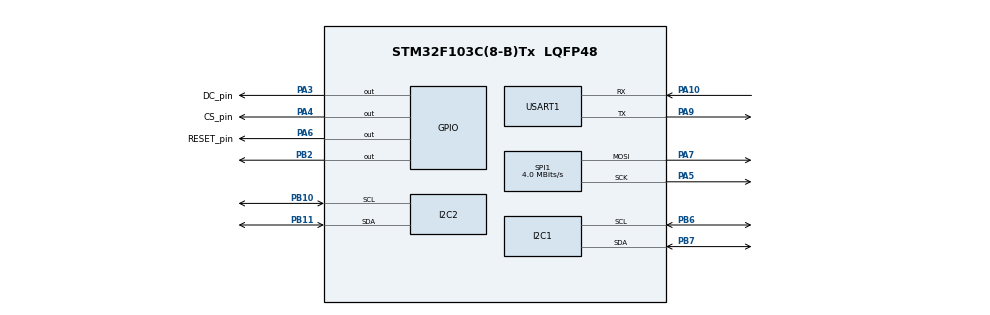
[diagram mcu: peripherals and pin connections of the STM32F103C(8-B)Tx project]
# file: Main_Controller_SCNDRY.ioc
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I2C1.OwnAddress=0x12
Mcu.Family=STM32F1
Mcu.Name=STM32F103C(8-B)Tx
Mcu.Package=LQFP48
NVIC.I2C1_ER_IRQn=true\:0\:0\:false\:false\:true\:true\:true\:true
NVIC.I2C1_EV_IRQn=true\:0\:0\:false\:false\:true\:true\:true\:true
NVIC.PriorityGroup=NVIC_PRIORITYGROUP_4
PA10.Mode=Asynchronous
PA10.Signal=USART1_RX
PA13.Mode=Serial_Wire
PA13.Signal=SYS_JTMS-SWDIO
PA14.Mode=Serial_Wire
PA14.Signal=SYS_JTCK-SWCLK
PA3.GPIO_Label=DC_pin
PA3.Signal=GPIO_Output
PA4.GPIO_Label=CS_pin
PA4.Signal=GPIO_Output
PA5.Mode=TX_Only_Simplex_Unidirect_Master
PA5.Signal=SPI1_SCK
PA6.GPIO_Label=RESET_pin
PA6.Signal=GPIO_Output
PA7.Mode=TX_Only_Simplex_Unidirect_Master
PA7.Signal=SPI1_MOSI
PA9.Mode=Asynchronous
PA9.Signal=USART1_TX
PB10.Mode=I2C
PB10.Signal=I2C2_SCL
PB11.Mode=I2C
PB11.Signal=I2C2_SDA
PB2.Signal=GPIO_Output
PB6.Mode=I2C
PB6.Signal=I2C1_SCL
PB7.Mode=I2C
PB7.Signal=I2C1_SDA
ProjectManager.HeapSize=0x200
ProjectManager.StackSize=0x400
ProjectManager.TargetToolchain=STM32CubeIDE
RCC.APB1Freq_Value=8000000
RCC.APB2Freq_Value=8000000
SPI1.CalculateBaudRate=4.0 MBits/s
SPI1.Direction=SPI_DIRECTION_2LINES
SPI1.Mode=SPI_MODE_MASTER
SPI1.VirtualType=VM_MASTER
USART1.VirtualMode=VM_ASYNC
board=custom

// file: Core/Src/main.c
//* USER CODE BEGIN Header */
/**
  ******************************************************************************
  * @file           : main.c
  * @brief          : Main program body
  ******************************************************************************
  * @attention
  *
  * Copyright (c) 2025 STMicroelectronics.
  * All rights reserved.
  *
  * This software is licensed under terms that can be found in the LICENSE file
  * in the root directory of this software component.
  * If no LICENSE file comes with this software, it is provided AS-IS.
  *
  ******************************************************************************
  */
/* USER CODE END Header */
#include "main.h"

/* USER CODE BEGIN Includes */
#include "I2C_Transmit.h"
#include "I2C_Receive.h"
#include "ssd1306.h"
#include "ssd1306_fonts.h"
#include "string.h"
#include "stdio.h"
/* USER CODE END Includes */

/* USER CODE BEGIN PD */
#define DO_Address 0x14
#define AO_Address 0x12
/* USER CODE END PD */

I2C_HandleTypeDef hi2c1;
I2C_HandleTypeDef hi2c2;

SPI_HandleTypeDef hspi1;

UART_HandleTypeDef huart1;

/* USER CODE BEGIN PV */
char analog_displayBuffer[4];
char digital_displayBuffer[9] = "";
/* USER CODE END PV */

void SystemClock_Config(void);
static void MX_GPIO_Init(void);
static void MX_I2C1_Init(void);
static void MX_I2C2_Init(void);
static void MX_SPI1_Init(void);
static void MX_USART1_UART_Init(void);

int main(void)
{

  /* MCU Configuration--------------------------------------------------------*/

  /* Reset of all peripherals, Initializes the Flash interface and the Systick. */
  HAL_Init();

  /* Configure the system clock */
  SystemClock_Config();

  /* Initialize all configured peripherals */
  MX_GPIO_Init();
  MX_I2C1_Init();
  MX_I2C2_Init();
  MX_SPI1_Init();
  MX_USART1_UART_Init();
  /* USER CODE BEGIN 2 */
  ssd1306_Init();
  uart_buffer[0] = 0xAA; // Start byte for data framing in ESP32
  /* USER CODE END 2 */

  /* Infinite loop */
  /* USER CODE BEGIN WHILE */
  while (1)
  {
	  /* For receiving data in interrupt mode*/
	HAL_I2C_EnableListen_IT(&hi2c1);

	/*for(int i = 0; i < 8; i++){
		digital_displayBuffer[i] = decodedBits[i] ? '1' : '0';
	}
	digital_displayBuffer[8] = '\0';

	sprintf(analog_displayBuffer, "%hu",analog_val);

	ssd1306_Fill(Black); // For the background color selection
	ssd1306_SetCursor(2, 0);	// To point to a pixel to start writing from
	ssd1306_WriteString("AO: ", Font_11x18, White); // To write the desired text on screen
	ssd1306_SetCursor(77,0);
	ssd1306_WriteString(analog_displayBuffer, Font_11x18 , White);
	ssd1306_SetCursor(2, 20);	// To point to a pixel to start writing from
	ssd1306_WriteString("DO: ", Font_11x18, White); // To write the desired text on screen
	ssd1306_SetCursor(35,20);
	ssd1306_WriteString(digital_displayBuffer, Font_11x18 , White);
	ssd1306_UpdateScreen();*/
	/* Transferring received data to digital output module
	* and analog output module
	*/
	//writeData(&digital_data,DO_Address,1);
	//HAL_UART_Transmit(&huart1, uart_buffer, 4, 1);
	writeData(analog_data, AO_Address, 2);
	//HAL_Delay(250);
    /* USER CODE END WHILE */

  }
}

void SystemClock_Config(void)
{
  RCC_OscInitTypeDef RCC_OscInitStruct = {0};
  RCC_ClkInitTypeDef RCC_ClkInitStruct = {0};

  /** Initializes the RCC Oscillators according to the specified parameters
  * in the RCC_OscInitTypeDef structure.
  */
  RCC_OscInitStruct.OscillatorType = RCC_OSCILLATORTYPE_HSI;
  RCC_OscInitStruct.HSIState = RCC_HSI_ON;
  RCC_OscInitStruct.HSICalibrationValue = RCC_HSICALIBRATION_DEFAULT;
  RCC_OscInitStruct.PLL.PLLState = RCC_PLL_NONE;
  if (HAL_RCC_OscConfig(&RCC_OscInitStruct) != HAL_OK)
  {
    Error_Handler();
  }

  /** Initializes the CPU, AHB and APB buses clocks
  */
  RCC_ClkInitStruct.ClockType = RCC_CLOCKTYPE_HCLK|RCC_CLOCKTYPE_SYSCLK
                              |RCC_CLOCKTYPE_PCLK1|RCC_CLOCKTYPE_PCLK2;
  RCC_ClkInitStruct.SYSCLKSource = RCC_SYSCLKSOURCE_HSI;
  RCC_ClkInitStruct.AHBCLKDivider = RCC_SYSCLK_DIV1;
  RCC_ClkInitStruct.APB1CLKDivider = RCC_HCLK_DIV1;
  RCC_ClkInitStruct.APB2CLKDivider = RCC_HCLK_DIV1;

  if (HAL_RCC_ClockConfig(&RCC_ClkInitStruct, FLASH_LATENCY_0) != HAL_OK)
  {
    Error_Handler();
  }
}

static void MX_I2C1_Init(void)
{

  hi2c1.Instance = I2C1;
  hi2c1.Init.ClockSpeed = 100000;
  hi2c1.Init.DutyCycle = I2C_DUTYCYCLE_2;
  hi2c1.Init.OwnAddress1 = 36;
  hi2c1.Init.AddressingMode = I2C_ADDRESSINGMODE_7BIT;
  hi2c1.Init.DualAddressMode = I2C_DUALADDRESS_DISABLE;
  hi2c1.Init.OwnAddress2 = 0;
  hi2c1.Init.GeneralCallMode = I2C_GENERALCALL_DISABLE;
  hi2c1.Init.NoStretchMode = I2C_NOSTRETCH_DISABLE;
  if (HAL_I2C_Init(&hi2c1) != HAL_OK)
  {
    Error_Handler();
  }

}

static void MX_I2C2_Init(void)
{

  hi2c2.Instance = I2C2;
  hi2c2.Init.ClockSpeed = 100000;
  hi2c2.Init.DutyCycle = I2C_DUTYCYCLE_2;
  hi2c2.Init.OwnAddress1 = 0;
  hi2c2.Init.AddressingMode = I2C_ADDRESSINGMODE_7BIT;
  hi2c2.Init.DualAddressMode = I2C_DUALADDRESS_DISABLE;
  hi2c2.Init.OwnAddress2 = 0;
  hi2c2.Init.GeneralCallMode = I2C_GENERALCALL_DISABLE;
  hi2c2.Init.NoStretchMode = I2C_NOSTRETCH_DISABLE;
  if (HAL_I2C_Init(&hi2c2) != HAL_OK)
  {
    Error_Handler();
  }

}

static void MX_SPI1_Init(void)
{

  /* SPI1 parameter configuration*/
  hspi1.Instance = SPI1;
  hspi1.Init.Mode = SPI_MODE_MASTER;
  hspi1.Init.Direction = SPI_DIRECTION_2LINES;
  hspi1.Init.DataSize = SPI_DATASIZE_8BIT;
  hspi1.Init.CLKPolarity = SPI_POLARITY_LOW;
  hspi1.Init.CLKPhase = SPI_PHASE_1EDGE;
  hspi1.Init.NSS = SPI_NSS_SOFT;
  hspi1.Init.BaudRatePrescaler = SPI_BAUDRATEPRESCALER_2;
  hspi1.Init.FirstBit = SPI_FIRSTBIT_MSB;
  hspi1.Init.TIMode = SPI_TIMODE_DISABLE;
  hspi1.Init.CRCCalculation = SPI_CRCCALCULATION_DISABLE;
  hspi1.Init.CRCPolynomial = 10;
  if (HAL_SPI_Init(&hspi1) != HAL_OK)
  {
    Error_Handler();
  }

}

static void MX_USART1_UART_Init(void)
{

  huart1.Instance = USART1;
  huart1.Init.BaudRate = 115200;
  huart1.Init.WordLength = UART_WORDLENGTH_8B;
  huart1.Init.StopBits = UART_STOPBITS_1;
  huart1.Init.Parity = UART_PARITY_NONE;
  huart1.Init.Mode = UART_MODE_TX_RX;
  huart1.Init.HwFlowCtl = UART_HWCONTROL_NONE;
  huart1.Init.OverSampling = UART_OVERSAMPLING_16;
  if (HAL_UART_Init(&huart1) != HAL_OK)
  {
    Error_Handler();
  }

}

static void MX_GPIO_Init(void)
{
  GPIO_InitTypeDef GPIO_InitStruct = {0};

  /* GPIO Ports Clock Enable */
  __HAL_RCC_GPIOA_CLK_ENABLE();
  __HAL_RCC_GPIOB_CLK_ENABLE();

  /*Configure GPIO pin Output Level */
  HAL_GPIO_WritePin(GPIOA, DC_pin_Pin|CS_pin_Pin|RESET_pin_Pin, GPIO_PIN_RESET);

  /*Configure GPIO pin Output Level */
  HAL_GPIO_WritePin(GPIOB, GPIO_PIN_2, GPIO_PIN_RESET);

  /*Configure GPIO pins : DC_pin_Pin CS_pin_Pin RESET_pin_Pin */
  GPIO_InitStruct.Pin = DC_pin_Pin|CS_pin_Pin|RESET_pin_Pin;
  GPIO_InitStruct.Mode = GPIO_MODE_OUTPUT_PP;
  GPIO_InitStruct.Pull = GPIO_NOPULL;
  GPIO_InitStruct.Speed = GPIO_SPEED_FREQ_LOW;
  HAL_GPIO_Init(GPIOA, &GPIO_InitStruct);

  /*Configure GPIO pin : PB2 */
  GPIO_InitStruct.Pin = GPIO_PIN_2;
  GPIO_InitStruct.Mode = GPIO_MODE_OUTPUT_PP;
  GPIO_InitStruct.Pull = GPIO_NOPULL;
  GPIO_InitStruct.Speed = GPIO_SPEED_FREQ_LOW;
  HAL_GPIO_Init(GPIOB, &GPIO_InitStruct);

}

void Error_Handler(void)
{
  __disable_irq();
  while (1)
  {
  }
}
